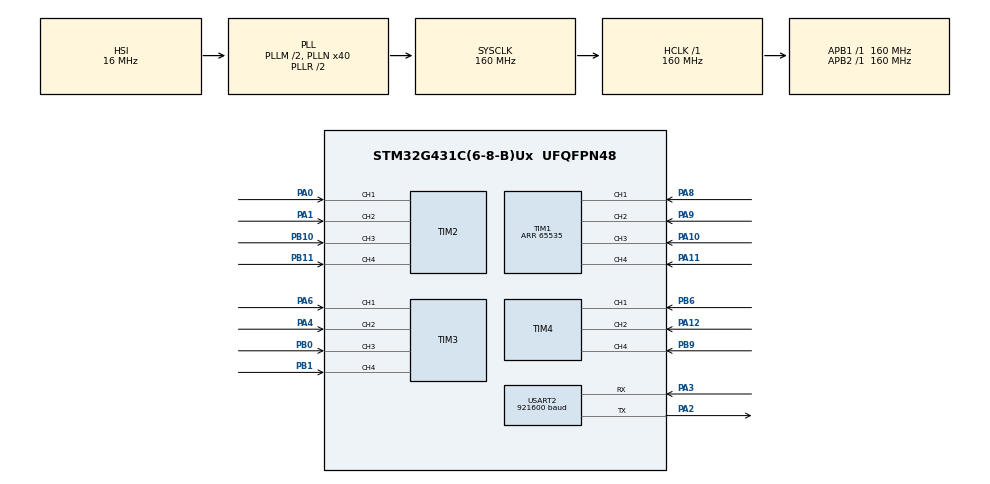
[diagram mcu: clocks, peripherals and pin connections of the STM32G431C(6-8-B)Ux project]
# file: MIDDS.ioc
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Mcu.Family=STM32G4
Mcu.Name=STM32G431C(6-8-B)Ux
Mcu.Package=UFQFPN48
NVIC.PriorityGroup=NVIC_PRIORITYGROUP_4
NVIC.TIM1_CC_IRQn=true\:0\:0\:true\:true\:true\:2\:true\:true\:true
NVIC.TIM1_UP_TIM16_IRQn=true\:0\:0\:true\:true\:true\:1\:true\:true\:true
NVIC.TIM2_IRQn=true\:0\:0\:false\:false\:true\:true\:true\:true
NVIC.TIM3_IRQn=true\:0\:0\:false\:false\:true\:true\:true\:true
NVIC.TIM4_IRQn=true\:0\:0\:false\:false\:true\:true\:true\:true
PA0.GPIO_PuPd=GPIO_PULLDOWN
PA0.GPIO_Speed=GPIO_SPEED_FREQ_VERY_HIGH
PA0.Signal=S_TIM2_CH1
PA1.GPIO_PuPd=GPIO_PULLDOWN
PA1.GPIO_Speed=GPIO_SPEED_FREQ_VERY_HIGH
PA1.Signal=S_TIM2_CH2
PA10.GPIO_PuPd=GPIO_PULLDOWN
PA10.GPIO_Speed=GPIO_SPEED_FREQ_VERY_HIGH
PA10.Signal=S_TIM1_CH3
PA11.GPIO_PuPd=GPIO_PULLDOWN
PA11.GPIO_Speed=GPIO_SPEED_FREQ_VERY_HIGH
PA11.Signal=S_TIM1_CH4
PA12.GPIO_PuPd=GPIO_PULLDOWN
PA12.GPIO_Speed=GPIO_SPEED_FREQ_VERY_HIGH
PA12.Signal=S_TIM4_CH2
PA2.GPIO_Speed=GPIO_SPEED_FREQ_VERY_HIGH
PA2.Mode=Asynchronous
PA2.Signal=USART2_TX
PA3.GPIO_Speed=GPIO_SPEED_FREQ_VERY_HIGH
PA3.Mode=Asynchronous
PA3.Signal=USART2_RX
PA4.GPIO_PuPd=GPIO_PULLDOWN
PA4.GPIO_Speed=GPIO_SPEED_FREQ_VERY_HIGH
PA4.Signal=S_TIM3_CH2
PA6.GPIO_PuPd=GPIO_PULLDOWN
PA6.GPIO_Speed=GPIO_SPEED_FREQ_VERY_HIGH
PA6.Signal=S_TIM3_CH1
PA8.GPIO_PuPd=GPIO_PULLDOWN
PA8.GPIO_Speed=GPIO_SPEED_FREQ_VERY_HIGH
PA8.Signal=S_TIM1_CH1
PA9.GPIO_PuPd=GPIO_PULLDOWN
PA9.GPIO_Speed=GPIO_SPEED_FREQ_VERY_HIGH
PA9.Signal=S_TIM1_CH2
PB0.GPIO_PuPd=GPIO_PULLDOWN
PB0.GPIO_Speed=GPIO_SPEED_FREQ_VERY_HIGH
PB0.Signal=S_TIM3_CH3
PB1.GPIO_PuPd=GPIO_PULLDOWN
PB1.GPIO_Speed=GPIO_SPEED_FREQ_VERY_HIGH
PB1.Signal=S_TIM3_CH4
PB10.GPIO_PuPd=GPIO_PULLDOWN
PB10.GPIO_Speed=GPIO_SPEED_FREQ_VERY_HIGH
PB10.Signal=S_TIM2_CH3
PB11.GPIO_PuPd=GPIO_PULLDOWN
PB11.GPIO_Speed=GPIO_SPEED_FREQ_VERY_HIGH
PB11.Signal=S_TIM2_CH4
PB6.GPIO_PuPd=GPIO_PULLDOWN
PB6.GPIO_Speed=GPIO_SPEED_FREQ_VERY_HIGH
PB6.Signal=S_TIM4_CH1
PB9.GPIO_PuPd=GPIO_PULLDOWN
PB9.GPIO_Speed=GPIO_SPEED_FREQ_VERY_HIGH
PB9.Signal=S_TIM4_CH4
PF0-OSC_IN.Mode=HSE-External-Oscillator
PF0-OSC_IN.Signal=RCC_OSC_IN
PF1-OSC_OUT.Mode=HSE-External-Oscillator
PF1-OSC_OUT.Signal=RCC_OSC_OUT
ProjectManager.HeapSize=0x200
ProjectManager.StackSize=0x400
ProjectManager.TargetToolchain=STM32CubeIDE
RCC.ADC12Freq_Value=160000000
RCC.AHBFreq_Value=160000000
RCC.APB1Freq_Value=160000000
RCC.APB1TimFreq_Value=160000000
RCC.APB2Freq_Value=160000000
RCC.APB2TimFreq_Value=160000000
RCC.CortexFreq_Value=160000000
RCC.EXTERNAL_CLOCK_VALUE=12288000
RCC.HCLKFreq_Value=160000000
RCC.HSE_VALUE=8000000
RCC.HSI48_VALUE=48000000
RCC.HSICalibrationValue=64
RCC.HSI_VALUE=16000000
RCC.LSE_VALUE=32768
RCC.PLLM=RCC_PLLM_DIV2
RCC.PLLN=40
RCC.SYSCLKFreq_VALUE=160000000
RCC.SYSCLKSource=RCC_SYSCLKSOURCE_PLLCLK
RCC.USBFreq_Value=160000000
RCC.VCOOutputFreq_Value=320000000
SH.S_TIM1_CH1.0=TIM1_CH1,Input_Capture1_from_TI1
SH.S_TIM1_CH2.0=TIM1_CH2,Input_Capture2_from_TI2
SH.S_TIM1_CH3.0=TIM1_CH3,Input_Capture3_from_TI3
SH.S_TIM1_CH4.0=TIM1_CH4,Input_Capture4_from_TI4
SH.S_TIM2_CH1.0=TIM2_CH1,Input_Capture1_from_TI1
SH.S_TIM2_CH2.0=TIM2_CH2,Input_Capture2_from_TI2
SH.S_TIM2_CH3.0=TIM2_CH3,Input_Capture3_from_TI3
SH.S_TIM2_CH4.0=TIM2_CH4,Input_Capture4_from_TI4
SH.S_TIM3_CH1.0=TIM3_CH1,Input_Capture1_from_TI1
SH.S_TIM3_CH2.0=TIM3_CH2,Input_Capture2_from_TI2
SH.S_TIM3_CH3.0=TIM3_CH3,Input_Capture3_from_TI3
SH.S_TIM3_CH4.0=TIM3_CH4,Input_Capture4_from_TI4
SH.S_TIM4_CH1.0=TIM4_CH1,Input_Capture1_from_TI1
SH.S_TIM4_CH2.0=TIM4_CH2,Input_Capture2_from_TI2
SH.S_TIM4_CH4.0=TIM4_CH4,Input_Capture4_from_TI4
TIM1.AutoReloadPreload=TIM_AUTORELOAD_PRELOAD_DISABLE
TIM1.Channel-Input_Capture1_from_TI1=TIM_CHANNEL_1
TIM1.Channel-Input_Capture2_from_TI2=TIM_CHANNEL_2
TIM1.Channel-Input_Capture3_from_TI3=TIM_CHANNEL_3
TIM1.Channel-Input_Capture4_from_TI4=TIM_CHANNEL_4
TIM1.ICPolarity_CH1=TIM_INPUTCHANNELPOLARITY_BOTHEDGE
TIM1.ICPolarity_CH2=TIM_INPUTCHANNELPOLARITY_BOTHEDGE
TIM1.ICPolarity_CH3=TIM_INPUTCHANNELPOLARITY_BOTHEDGE
TIM1.ICPolarity_CH4=TIM_INPUTCHANNELPOLARITY_BOTHEDGE
TIM1.PeriodNoDither=65535
TIM1.RepetitionCounter=0
TIM1.TIM_MasterOutputTrigger=TIM_TRGO_UPDATE
TIM2.Channel-Input_Capture1_from_TI1=TIM_CHANNEL_1
TIM2.Channel-Input_Capture2_from_TI2=TIM_CHANNEL_2
TIM2.Channel-Input_Capture3_from_TI3=TIM_CHANNEL_3
TIM2.Channel-Input_Capture4_from_TI4=TIM_CHANNEL_4
TIM2.ICPolarity_CH1=TIM_INPUTCHANNELPOLARITY_BOTHEDGE
TIM2.ICPolarity_CH2=TIM_INPUTCHANNELPOLARITY_BOTHEDGE
TIM2.ICPolarity_CH3=TIM_INPUTCHANNELPOLARITY_BOTHEDGE
TIM2.ICPolarity_CH4=TIM_INPUTCHANNELPOLARITY_BOTHEDGE
TIM3.Channel-Input_Capture1_from_TI1=TIM_CHANNEL_1
TIM3.Channel-Input_Capture2_from_TI2=TIM_CHANNEL_2
TIM3.Channel-Input_Capture3_from_TI3=TIM_CHANNEL_3
TIM3.Channel-Input_Capture4_from_TI4=TIM_CHANNEL_4
TIM3.ICPolarity_CH1=TIM_INPUTCHANNELPOLARITY_BOTHEDGE
TIM3.ICPolarity_CH2=TIM_INPUTCHANNELPOLARITY_BOTHEDGE
TIM3.ICPolarity_CH3=TIM_INPUTCHANNELPOLARITY_BOTHEDGE
TIM3.ICPolarity_CH4=TIM_INPUTCHANNELPOLARITY_BOTHEDGE
TIM4.Channel-Input_Capture1_from_TI1=TIM_CHANNEL_1
TIM4.Channel-Input_Capture2_from_TI2=TIM_CHANNEL_2
TIM4.Channel-Input_Capture4_from_TI4=TIM_CHANNEL_4
TIM4.ICPolarity_CH1=TIM_INPUTCHANNELPOLARITY_BOTHEDGE
TIM4.ICPolarity_CH2=TIM_INPUTCHANNELPOLARITY_BOTHEDGE
TIM4.ICPolarity_CH4=TIM_INPUTCHANNELPOLARITY_BOTHEDGE
USART2.BaudRate=921600
USART2.DMADisableonRxErrorParam=ADVFEATURE_DMA_DISABLEONRXERROR
USART2.OverSampling=UART_OVERSAMPLING_16
USART2.OverrunDisableParam=ADVFEATURE_OVERRUN_DISABLE
USART2.VirtualMode-Asynchronous=VM_ASYNC
VP_SYS_VS_DBSignals.Mode=DisableDeadBatterySignals
VP_TIM1_VS_ClockSourceINT.Mode=Internal
VP_TIM2_VS_ClockSourceINT.Mode=Internal
VP_TIM2_VS_ClockSourceITR.Mode=TriggerSource_ITR0
VP_TIM2_VS_ControllerModeReset.Mode=Reset Mode
VP_TIM3_VS_ClockSourceINT.Mode=Internal
VP_TIM3_VS_ClockSourceITR.Mode=TriggerSource_ITR0
VP_TIM3_VS_ControllerModeReset.Mode=Reset Mode
VP_TIM4_VS_ClockSourceINT.Mode=Internal
VP_TIM4_VS_ClockSourceITR.Mode=TriggerSource_ITR0
VP_TIM4_VS_ControllerModeReset.Mode=Reset Mode
board=custom

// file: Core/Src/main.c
/* USER CODE BEGIN Header */
/**
  ******************************************************************************
  * @file           : main.c
  * @brief          : Main program body
  ******************************************************************************
  * @attention
  *
  * Copyright (c) 2024 STMicroelectronics.
  * All rights reserved.
  *
  * This software is licensed under terms that can be found in the LICENSE file
  * in the root directory of this software component.
  * If no LICENSE file comes with this software, it is provided AS-IS.
  *
  ******************************************************************************
  */
/* USER CODE END Header */
#include "main.h"

/* USER CODE BEGIN Includes */
#include "MainMCU.h"
/* USER CODE END Includes */

TIM_HandleTypeDef htim1;
TIM_HandleTypeDef htim2;
TIM_HandleTypeDef htim3;
TIM_HandleTypeDef htim4;

UART_HandleTypeDef huart2;

void SystemClock_Config(void);
static void MX_GPIO_Init(void);
static void MX_TIM1_Init(void);
static void MX_USART2_UART_Init(void);
static void MX_TIM2_Init(void);
static void MX_TIM3_Init(void);
static void MX_TIM4_Init(void);
static void MX_NVIC_Init(void);

int main(void)
{

  /* MCU Configuration--------------------------------------------------------*/

  /* Reset of all peripherals, Initializes the Flash interface and the Systick. */
  HAL_Init();

  /* Configure the system clock */
  SystemClock_Config();

  /* Initialize all configured peripherals */
  MX_GPIO_Init();
  MX_TIM1_Init();
  MX_USART2_UART_Init();
  MX_TIM2_Init();
  MX_TIM3_Init();
  MX_TIM4_Init();

  /* Initialize interrupts */
  MX_NVIC_Init();
  /* USER CODE BEGIN 2 */
  initMCU(&htim1, &htim2, &htim3, &htim4, &huart2);
  /* USER CODE END 2 */

  /* Infinite loop */
  while (1)
  {

    /* USER CODE BEGIN 3 */
    loopMCU();
  }
  /* USER CODE END 3 */
}

void SystemClock_Config(void)
{
  RCC_OscInitTypeDef RCC_OscInitStruct = {0};
  RCC_ClkInitTypeDef RCC_ClkInitStruct = {0};

  /** Configure the main internal regulator output voltage
  */
  HAL_PWREx_ControlVoltageScaling(PWR_REGULATOR_VOLTAGE_SCALE1_BOOST);

  /** Initializes the RCC Oscillators according to the specified parameters
  * in the RCC_OscInitTypeDef structure.
  */
  RCC_OscInitStruct.OscillatorType = RCC_OSCILLATORTYPE_HSI;
  RCC_OscInitStruct.HSIState = RCC_HSI_ON;
  RCC_OscInitStruct.HSICalibrationValue = RCC_HSICALIBRATION_DEFAULT;
  RCC_OscInitStruct.PLL.PLLState = RCC_PLL_ON;
  RCC_OscInitStruct.PLL.PLLSource = RCC_PLLSOURCE_HSI;
  RCC_OscInitStruct.PLL.PLLM = RCC_PLLM_DIV2;
  RCC_OscInitStruct.PLL.PLLN = 40;
  RCC_OscInitStruct.PLL.PLLP = RCC_PLLP_DIV2;
  RCC_OscInitStruct.PLL.PLLQ = RCC_PLLQ_DIV2;
  RCC_OscInitStruct.PLL.PLLR = RCC_PLLR_DIV2;
  if (HAL_RCC_OscConfig(&RCC_OscInitStruct) != HAL_OK)
  {
    Error_Handler();
  }

  /** Initializes the CPU, AHB and APB buses clocks
  */
  RCC_ClkInitStruct.ClockType = RCC_CLOCKTYPE_HCLK|RCC_CLOCKTYPE_SYSCLK
                              |RCC_CLOCKTYPE_PCLK1|RCC_CLOCKTYPE_PCLK2;
  RCC_ClkInitStruct.SYSCLKSource = RCC_SYSCLKSOURCE_PLLCLK;
  RCC_ClkInitStruct.AHBCLKDivider = RCC_SYSCLK_DIV1;
  RCC_ClkInitStruct.APB1CLKDivider = RCC_HCLK_DIV1;
  RCC_ClkInitStruct.APB2CLKDivider = RCC_HCLK_DIV1;

  if (HAL_RCC_ClockConfig(&RCC_ClkInitStruct, FLASH_LATENCY_4) != HAL_OK)
  {
    Error_Handler();
  }
}

/**
  * @brief NVIC Configuration.
  * @retval None
  */
static void MX_NVIC_Init(void)
{
  /* TIM1_UP_TIM16_IRQn interrupt configuration */
  HAL_NVIC_SetPriority(TIM1_UP_TIM16_IRQn, 0, 0);
  HAL_NVIC_EnableIRQ(TIM1_UP_TIM16_IRQn);
  /* TIM1_CC_IRQn interrupt configuration */
  HAL_NVIC_SetPriority(TIM1_CC_IRQn, 0, 0);
  HAL_NVIC_EnableIRQ(TIM1_CC_IRQn);
}

static void MX_TIM1_Init(void)
{

  TIM_ClockConfigTypeDef sClockSourceConfig = {0};
  TIM_MasterConfigTypeDef sMasterConfig = {0};
  TIM_IC_InitTypeDef sConfigIC = {0};

  htim1.Instance = TIM1;
  htim1.Init.Prescaler = 0;
  htim1.Init.CounterMode = TIM_COUNTERMODE_UP;
  htim1.Init.Period = 65535;
  htim1.Init.ClockDivision = TIM_CLOCKDIVISION_DIV1;
  htim1.Init.RepetitionCounter = 0;
  htim1.Init.AutoReloadPreload = TIM_AUTORELOAD_PRELOAD_DISABLE;
  if (HAL_TIM_Base_Init(&htim1) != HAL_OK)
  {
    Error_Handler();
  }
  sClockSourceConfig.ClockSource = TIM_CLOCKSOURCE_INTERNAL;
  if (HAL_TIM_ConfigClockSource(&htim1, &sClockSourceConfig) != HAL_OK)
  {
    Error_Handler();
  }
  if (HAL_TIM_IC_Init(&htim1) != HAL_OK)
  {
    Error_Handler();
  }
  sMasterConfig.MasterOutputTrigger = TIM_TRGO_UPDATE;
  sMasterConfig.MasterOutputTrigger2 = TIM_TRGO2_RESET;
  sMasterConfig.MasterSlaveMode = TIM_MASTERSLAVEMODE_DISABLE;
  if (HAL_TIMEx_MasterConfigSynchronization(&htim1, &sMasterConfig) != HAL_OK)
  {
    Error_Handler();
  }
  sConfigIC.ICPolarity = TIM_INPUTCHANNELPOLARITY_BOTHEDGE;
  sConfigIC.ICSelection = TIM_ICSELECTION_DIRECTTI;
  sConfigIC.ICPrescaler = TIM_ICPSC_DIV1;
  sConfigIC.ICFilter = 0;
  if (HAL_TIM_IC_ConfigChannel(&htim1, &sConfigIC, TIM_CHANNEL_1) != HAL_OK)
  {
    Error_Handler();
  }
  if (HAL_TIM_IC_ConfigChannel(&htim1, &sConfigIC, TIM_CHANNEL_2) != HAL_OK)
  {
    Error_Handler();
  }
  if (HAL_TIM_IC_ConfigChannel(&htim1, &sConfigIC, TIM_CHANNEL_3) != HAL_OK)
  {
    Error_Handler();
  }
  if (HAL_TIM_IC_ConfigChannel(&htim1, &sConfigIC, TIM_CHANNEL_4) != HAL_OK)
  {
    Error_Handler();
  }

}

static void MX_TIM2_Init(void)
{

  TIM_ClockConfigTypeDef sClockSourceConfig = {0};
  TIM_SlaveConfigTypeDef sSlaveConfig = {0};
  TIM_MasterConfigTypeDef sMasterConfig = {0};
  TIM_IC_InitTypeDef sConfigIC = {0};

  htim2.Instance = TIM2;
  htim2.Init.Prescaler = 0;
  htim2.Init.CounterMode = TIM_COUNTERMODE_UP;
  htim2.Init.Period = 4294967295;
  htim2.Init.ClockDivision = TIM_CLOCKDIVISION_DIV1;
  htim2.Init.AutoReloadPreload = TIM_AUTORELOAD_PRELOAD_DISABLE;
  if (HAL_TIM_Base_Init(&htim2) != HAL_OK)
  {
    Error_Handler();
  }
  sClockSourceConfig.ClockSource = TIM_CLOCKSOURCE_INTERNAL;
  if (HAL_TIM_ConfigClockSource(&htim2, &sClockSourceConfig) != HAL_OK)
  {
    Error_Handler();
  }
  if (HAL_TIM_IC_Init(&htim2) != HAL_OK)
  {
    Error_Handler();
  }
  sSlaveConfig.SlaveMode = TIM_SLAVEMODE_RESET;
  sSlaveConfig.InputTrigger = TIM_TS_ITR0;
  if (HAL_TIM_SlaveConfigSynchro(&htim2, &sSlaveConfig) != HAL_OK)
  {
    Error_Handler();
  }
  sMasterConfig.MasterOutputTrigger = TIM_TRGO_RESET;
  sMasterConfig.MasterSlaveMode = TIM_MASTERSLAVEMODE_DISABLE;
  if (HAL_TIMEx_MasterConfigSynchronization(&htim2, &sMasterConfig) != HAL_OK)
  {
    Error_Handler();
  }
  sConfigIC.ICPolarity = TIM_INPUTCHANNELPOLARITY_BOTHEDGE;
  sConfigIC.ICSelection = TIM_ICSELECTION_DIRECTTI;
  sConfigIC.ICPrescaler = TIM_ICPSC_DIV1;
  sConfigIC.ICFilter = 0;
  if (HAL_TIM_IC_ConfigChannel(&htim2, &sConfigIC, TIM_CHANNEL_1) != HAL_OK)
  {
    Error_Handler();
  }
  if (HAL_TIM_IC_ConfigChannel(&htim2, &sConfigIC, TIM_CHANNEL_2) != HAL_OK)
  {
    Error_Handler();
  }
  if (HAL_TIM_IC_ConfigChannel(&htim2, &sConfigIC, TIM_CHANNEL_3) != HAL_OK)
  {
    Error_Handler();
  }
  if (HAL_TIM_IC_ConfigChannel(&htim2, &sConfigIC, TIM_CHANNEL_4) != HAL_OK)
  {
    Error_Handler();
  }

}

static void MX_TIM3_Init(void)
{

  TIM_ClockConfigTypeDef sClockSourceConfig = {0};
  TIM_SlaveConfigTypeDef sSlaveConfig = {0};
  TIM_MasterConfigTypeDef sMasterConfig = {0};
  TIM_IC_InitTypeDef sConfigIC = {0};

  htim3.Instance = TIM3;
  htim3.Init.Prescaler = 0;
  htim3.Init.CounterMode = TIM_COUNTERMODE_UP;
  htim3.Init.Period = 65535;
  htim3.Init.ClockDivision = TIM_CLOCKDIVISION_DIV1;
  htim3.Init.AutoReloadPreload = TIM_AUTORELOAD_PRELOAD_DISABLE;
  if (HAL_TIM_Base_Init(&htim3) != HAL_OK)
  {
    Error_Handler();
  }
  sClockSourceConfig.ClockSource = TIM_CLOCKSOURCE_INTERNAL;
  if (HAL_TIM_ConfigClockSource(&htim3, &sClockSourceConfig) != HAL_OK)
  {
    Error_Handler();
  }
  if (HAL_TIM_IC_Init(&htim3) != HAL_OK)
  {
    Error_Handler();
  }
  sSlaveConfig.SlaveMode = TIM_SLAVEMODE_RESET;
  sSlaveConfig.InputTrigger = TIM_TS_ITR0;
  if (HAL_TIM_SlaveConfigSynchro(&htim3, &sSlaveConfig) != HAL_OK)
  {
    Error_Handler();
  }
  sMasterConfig.MasterOutputTrigger = TIM_TRGO_RESET;
  sMasterConfig.MasterSlaveMode = TIM_MASTERSLAVEMODE_DISABLE;
  if (HAL_TIMEx_MasterConfigSynchronization(&htim3, &sMasterConfig) != HAL_OK)
  {
    Error_Handler();
  }
  sConfigIC.ICPolarity = TIM_INPUTCHANNELPOLARITY_BOTHEDGE;
  sConfigIC.ICSelection = TIM_ICSELECTION_DIRECTTI;
  sConfigIC.ICPrescaler = TIM_ICPSC_DIV1;
  sConfigIC.ICFilter = 0;
  if (HAL_TIM_IC_ConfigChannel(&htim3, &sConfigIC, TIM_CHANNEL_1) != HAL_OK)
  {
    Error_Handler();
  }
  if (HAL_TIM_IC_ConfigChannel(&htim3, &sConfigIC, TIM_CHANNEL_2) != HAL_OK)
  {
    Error_Handler();
  }
  if (HAL_TIM_IC_ConfigChannel(&htim3, &sConfigIC, TIM_CHANNEL_3) != HAL_OK)
  {
    Error_Handler();
  }
  if (HAL_TIM_IC_ConfigChannel(&htim3, &sConfigIC, TIM_CHANNEL_4) != HAL_OK)
  {
    Error_Handler();
  }

}

static void MX_TIM4_Init(void)
{

  TIM_ClockConfigTypeDef sClockSourceConfig = {0};
  TIM_SlaveConfigTypeDef sSlaveConfig = {0};
  TIM_MasterConfigTypeDef sMasterConfig = {0};
  TIM_IC_InitTypeDef sConfigIC = {0};

  htim4.Instance = TIM4;
  htim4.Init.Prescaler = 0;
  htim4.Init.CounterMode = TIM_COUNTERMODE_UP;
  htim4.Init.Period = 65535;
  htim4.Init.ClockDivision = TIM_CLOCKDIVISION_DIV1;
  htim4.Init.AutoReloadPreload = TIM_AUTORELOAD_PRELOAD_DISABLE;
  if (HAL_TIM_Base_Init(&htim4) != HAL_OK)
  {
    Error_Handler();
  }
  sClockSourceConfig.ClockSource = TIM_CLOCKSOURCE_INTERNAL;
  if (HAL_TIM_ConfigClockSource(&htim4, &sClockSourceConfig) != HAL_OK)
  {
    Error_Handler();
  }
  if (HAL_TIM_IC_Init(&htim4) != HAL_OK)
  {
    Error_Handler();
  }
  sSlaveConfig.SlaveMode = TIM_SLAVEMODE_RESET;
  sSlaveConfig.InputTrigger = TIM_TS_ITR0;
  if (HAL_TIM_SlaveConfigSynchro(&htim4, &sSlaveConfig) != HAL_OK)
  {
    Error_Handler();
  }
  sMasterConfig.MasterOutputTrigger = TIM_TRGO_RESET;
  sMasterConfig.MasterSlaveMode = TIM_MASTERSLAVEMODE_DISABLE;
  if (HAL_TIMEx_MasterConfigSynchronization(&htim4, &sMasterConfig) != HAL_OK)
  {
    Error_Handler();
  }
  sConfigIC.ICPolarity = TIM_INPUTCHANNELPOLARITY_BOTHEDGE;
  sConfigIC.ICSelection = TIM_ICSELECTION_DIRECTTI;
  sConfigIC.ICPrescaler = TIM_ICPSC_DIV1;
  sConfigIC.ICFilter = 0;
  if (HAL_TIM_IC_ConfigChannel(&htim4, &sConfigIC, TIM_CHANNEL_1) != HAL_OK)
  {
    Error_Handler();
  }
  if (HAL_TIM_IC_ConfigChannel(&htim4, &sConfigIC, TIM_CHANNEL_2) != HAL_OK)
  {
    Error_Handler();
  }
  if (HAL_TIM_IC_ConfigChannel(&htim4, &sConfigIC, TIM_CHANNEL_4) != HAL_OK)
  {
    Error_Handler();
  }

}

static void MX_USART2_UART_Init(void)
{

  huart2.Instance = USART2;
  huart2.Init.BaudRate = 921600;
  huart2.Init.WordLength = UART_WORDLENGTH_8B;
  huart2.Init.StopBits = UART_STOPBITS_1;
  huart2.Init.Parity = UART_PARITY_NONE;
  huart2.Init.Mode = UART_MODE_TX_RX;
  huart2.Init.HwFlowCtl = UART_HWCONTROL_NONE;
  huart2.Init.OverSampling = UART_OVERSAMPLING_16;
  huart2.Init.OneBitSampling = UART_ONE_BIT_SAMPLE_DISABLE;
  huart2.Init.ClockPrescaler = UART_PRESCALER_DIV1;
  huart2.AdvancedInit.AdvFeatureInit = UART_ADVFEATURE_RXOVERRUNDISABLE_INIT|UART_ADVFEATURE_DMADISABLEONERROR_INIT;
  huart2.AdvancedInit.OverrunDisable = UART_ADVFEATURE_OVERRUN_DISABLE;
  huart2.AdvancedInit.DMADisableonRxError = UART_ADVFEATURE_DMA_DISABLEONRXERROR;
  if (HAL_UART_Init(&huart2) != HAL_OK)
  {
    Error_Handler();
  }
  if (HAL_UARTEx_SetTxFifoThreshold(&huart2, UART_TXFIFO_THRESHOLD_1_8) != HAL_OK)
  {
    Error_Handler();
  }
  if (HAL_UARTEx_SetRxFifoThreshold(&huart2, UART_RXFIFO_THRESHOLD_1_8) != HAL_OK)
  {
    Error_Handler();
  }
  if (HAL_UARTEx_DisableFifoMode(&huart2) != HAL_OK)
  {
    Error_Handler();
  }

}

static void MX_GPIO_Init(void)
{

  /* GPIO Ports Clock Enable */
  __HAL_RCC_GPIOF_CLK_ENABLE();
  __HAL_RCC_GPIOA_CLK_ENABLE();
  __HAL_RCC_GPIOB_CLK_ENABLE();

}

void Error_Handler(void)
{
  __disable_irq();
  while (1)
  {
  }
}
